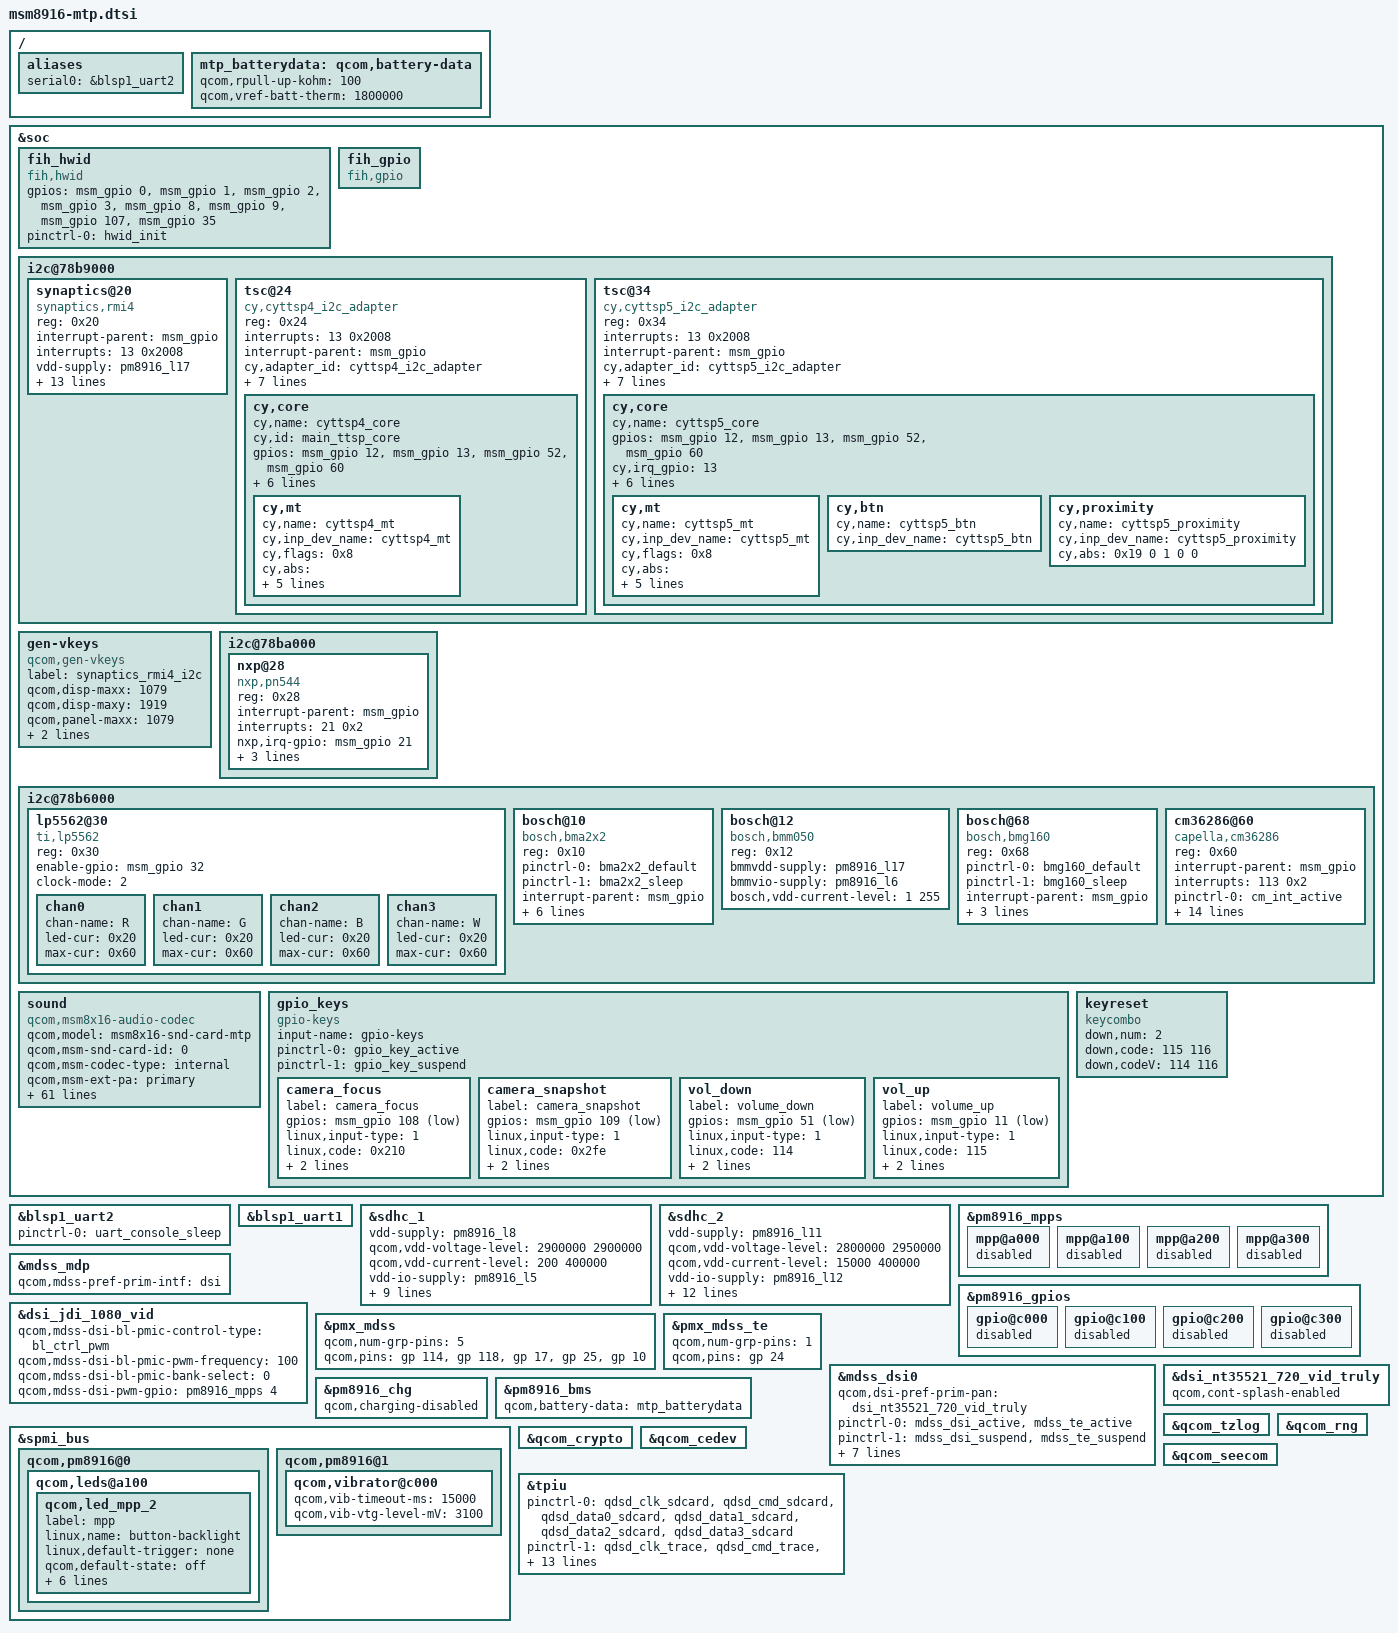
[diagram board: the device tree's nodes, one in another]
/* Copyright (c) 2014, The Linux Foundation. All rights reserved.
 *
 * This program is free software; you can redistribute it and/or modify
 * it under the terms of the GNU General Public License version 2 and
 * only version 2 as published by the Free Software Foundation.
 *
 * This program is distributed in the hope that it will be useful,
 * but WITHOUT ANY WARRANTY; without even the implied warranty of
 * MERCHANTABILITY or FITNESS FOR A PARTICULAR PURPOSE.  See the
 * GNU General Public License for more details.
 */

#include "msm8916.dtsi"
#include "msm8916-pinctrl.dtsi"
/* #include "msm8916-camera-sensor-mtp.dtsi" *//* MM-MC-BringUpImx214CameraSensor-00- */
#include "msm8916-camera-sensor-mtp-fih.dtsi"/* MM-MC-BringUpImx214CameraSensor-00+ */

/ {
	aliases {
		serial0 = &blsp1_uart2;
	};
};

&soc {
    fih_hwid {
        compatible = "fih,hwid";
        /*the gpios order must from 0-7*/
        gpios = <&msm_gpio 0 0>,   /*HW_ID_0*/
                <&msm_gpio 1 0>,   /*HW_ID_1*/
                <&msm_gpio 2 0>,   /*HW_ID_2*/
                <&msm_gpio 3 0>,   /*HW_ID_3*/
                <&msm_gpio 8 0>,   /*HW_ID_4*/
                <&msm_gpio 9 0>,   /*HW_ID_5*/
                <&msm_gpio 107 0>, /*HW_ID_6*/
                <&msm_gpio 35 0>;  /*HW_ID_7*/
        pinctrl-names = "init";
        pinctrl-0 = <&hwid_init>;
    };

    fih_gpio {
        compatible = "fih,gpio";
    };

	i2c@78b9000 { /* BLSP1 QUP5 */
		synaptics@20 {
			compatible = "synaptics,rmi4";
			reg = <0x20>;
			interrupt-parent = <&msm_gpio>;
			interrupts = <13 0x2008>;
			vdd-supply = <&pm8916_l17>;
			vcc_i2c-supply = <&pm8916_l6>;
			/* pins used by touchscreen */
			pinctrl-names = "pmx_ts_active","pmx_ts_suspend","pmx_ts_suspend";
			pinctrl-0 = <&ts_int_active &ts_reset_active>;
			pinctrl-1 = <&ts_int_suspend &ts_reset_suspend>;
			pinctrl-2 = <&ts_release>;
			synaptics,display-coords = <0 0 1079 1919>;
			synaptics,panel-coords = <0 0 1079 2084>;
			synaptics,irq-gpio = <&msm_gpio 13 0x2008>;
			synaptics,reset-gpio = <&msm_gpio 12 0x0>;
			synaptics,i2c-pull-up;
			synaptics,power-down;
			synaptics,disable-gpios;
			/* Underlying clocks used by secure touch */
			clocks = <&clock_gcc clk_gcc_blsp1_ahb_clk>,
			 <&clock_gcc clk_gcc_blsp1_qup5_i2c_apps_clk>;
			clock-names = "iface_clk", "core_clk";
		};

		tsc@24 {
			compatible = "cy,cyttsp4_i2c_adapter";
			reg = <0x24>;
			/* GPIO 38, high-to-low edge triggered */
			interrupts = <13 0x2008>;
			interrupt-parent = <&msm_gpio>;
			cy,adapter_id = "cyttsp4_i2c_adapter";
			pinctrl-names = "pmx_ts_active","pmx_ts_suspend";
			pinctrl-0 = <&ts_int_active &ts_reset_active>;
			pinctrl-1 = <&ts_int_suspend &ts_reset_suspend>;
			vdda-supply = <&pm8916_l17>;
			vddio_EVM-supply = <&pm8916_l6>;
			vddio_PD1-supply = <&pm8916_l16>;
			vddio_DEFAULT-supply = <&pm8916_l6>;
			qcom,module_adc-vadc = <&pm8916_vadc>;

			cy,core {
				cy,name = "cyttsp4_core";
				cy,id = "main_ttsp_core";

				gpios = <&msm_gpio 12 0>, <&msm_gpio 13 0>, <&msm_gpio 52 0>, <&msm_gpio 60 0>;

				cy,irq_gpio = <13>;
				cy,rst_gpio = <12>;

				/* Enable cy,max_xfer_len to limit max I2C/SPI transfer length */
				/* cy,max_xfer_len = <0x100>; */

				/* CY_CORE_FLAG_WAKE_ON_GESTURE */
				cy,flags = <1>;
				/* CY_CORE_EWG_TAP_TAP | CY_CORE_EWG_TWO_FINGER_SLIDE */
				cy,easy_wakeup_gesture = <3>;
				cy,btn_keys = <102 /* KEY_HOME */
					       139 /* KEY_MENU */
					       158 /* KEY_BACK */
					       217 /* KEY_SEARCH */
					       114 /* KEY_VOLUMEDOWN */
					       115 /* KEY_VOLUMEUP */
					       212 /* KEY_CAMERA */
					       116>; /* KEY_POWER */
				cy,btn_keys-tag = <0>;

				cy,mt {
					cy,name = "cyttsp4_mt";

					cy,inp_dev_name = "cyttsp4_mt";
					/* CY_MT_FLAG_FLIP | CY_MT_FLAG_INV_X | CY_MT_FLAG_INV_Y */
					cy,flags = <0x8>;
					cy,abs =
						/* ABS_MT_POSITION_X, CY_ABS_MIN_X, CY_ABS_MAX_X, 0, 0 */
						<0x35 0 1080 0 0
						/* ABS_MT_POSITION_Y, CY_ABS_MIN_Y, CY_ABS_MAX_Y, 0, 0 */
						0x36 0 1920 0 0
						/* ABS_MT_PRESSURE, CY_ABS_MIN_P, CY_ABS_MAX_P, 0, 0 */
						0x3a 0 255 0 0
						/* CY_IGNORE_VALUE, CY_ABS_MIN_W, CY_ABS_MAX_W, 0, 0 */
						0xffff 0 255 0 0
						/* ABS_MT_TRACKING_ID, CY_ABS_MIN_T, CY_ABS_MAX_T, 0, 0 */
						0x39 0 15 0 0
						/* ABS_MT_TOUCH_MAJOR, 0, 255, 0, 0 */
						0x30 0 255 0 0
						/* ABS_MT_TOUCH_MINOR, 0, 255, 0, 0 */
						0x31 0 255 0 0
						/* ABS_MT_ORIENTATION, -128, 127, 0, 0 */
						0x34 0xfffffed7 127 0 0>;

					cy,vkeys_x = <720>;
					cy,vkeys_y = <1280>;

					cy,virtual_keys = /* KeyCode CenterX CenterY Width Height */
						/* KEY_BACK */
						<158 1360 90 160 180
						/* KEY_MENU */
						139 1360 270 160 180
						/* KEY_HOME */
						102 1360 450 160 180
						/* KEY SEARCH */
						217 1360 630 160 180>;
				};
			};
		};

		tsc@34 {
			compatible = "cy,cyttsp5_i2c_adapter";
			reg = <0x34>;

			/* GPIO 38, high-to-low edge triggered */
			interrupts = <13 0x2008>;
			interrupt-parent = <&msm_gpio>;
			cy,adapter_id = "cyttsp5_i2c_adapter";
			pinctrl-names = "pmx_ts_active","pmx_ts_suspend";
			pinctrl-0 = <&ts_int_active &ts_reset_active>;
			pinctrl-1 = <&ts_int_suspend &ts_reset_suspend>;
			vdda-supply = <&pm8916_l17>;
			vddio_EVM-supply = <&pm8916_l6>;
			vddio_PD1-supply = <&pm8916_l16>;
			vddio_DEFAULT-supply = <&pm8916_l6>;
			qcom,module_adc-vadc = <&pm8916_vadc>;

			cy,core {
				cy,name = "cyttsp5_core";

				gpios = <&msm_gpio 12 0>, <&msm_gpio 13 0>, <&msm_gpio 52 0>, <&msm_gpio 60 0>;

				cy,irq_gpio = <13>;
				cy,rst_gpio = <12>;
				cy,hid_desc_register = <1>;
				/* CY_CORE_FLAG_WAKE_ON_GESTURE | CY_CORE_FLAG_RESTORE_PARAMETERS */
				cy,flags = <5>;
				/* CY_CORE_EWG_NONE */
				cy,easy_wakeup_gesture = <0>;
				cy,btn_keys = <172 /* KEY_HOMEPAGE */
						   /* previously was KEY_HOME, new Android versions use KEY_HOMEPAGE */
					       139 /* KEY_MENU */
					       158 /* KEY_BACK */
					       217 /* KEY_SEARCH */
					       114 /* KEY_VOLUMEDOWN */
					       115 /* KEY_VOLUMEUP */
					       212 /* KEY_CAMERA */
					       116>; /* KEY_POWER */
				cy,btn_keys-tag = <0>;

				cy,mt {
					cy,name = "cyttsp5_mt";

					cy,inp_dev_name = "cyttsp5_mt";
					/* CY_MT_FLAG_FLIP | CY_MT_FLAG_INV_X | CY_MT_FLAG_INV_Y */
					cy,flags = <0x8>;
					cy,abs =
						/* ABS_MT_POSITION_X, CY_ABS_MIN_X, CY_ABS_MAX_X, 0, 0 */
						<0x35 0 1080 0 0
						/* ABS_MT_POSITION_Y, CY_ABS_MIN_Y, CY_ABS_MAX_Y, 0, 0 */
						0x36 0 1920 0 0
						/* ABS_MT_PRESSURE, CY_ABS_MIN_P, CY_ABS_MAX_P, 0, 0 */
						0x3a 0 255 0 0
						/* CY_IGNORE_VALUE, CY_ABS_MIN_W, CY_ABS_MAX_W, 0, 0 */
						0xffff 0 255 0 0
						/* ABS_MT_TRACKING_ID, CY_ABS_MIN_T, CY_ABS_MAX_T, 0, 0 */
						0x39 0 15 0 0
						/* ABS_MT_TOUCH_MAJOR, 0, 255, 0, 0 */
						0x30 0 255 0 0
						/* ABS_MT_TOUCH_MINOR, 0, 255, 0, 0 */
						0x31 0 255 0 0
						/* ABS_MT_ORIENTATION, -127, 127, 0, 0 */
						0x34 0xffffff81 127 0 0
						/* ABS_MT_TOOL_TYPE, 0, MT_TOOL_MAX, 0, 0 */
						0x37 0 1 0 0
						/* ABS_DISTANCE, 0, 255, 0, 0 */
						0x19 0 255 0 0>;

					cy,vkeys_x = <720>;
					cy,vkeys_y = <1280>;

					cy,virtual_keys = /* KeyCode CenterX CenterY Width Height */
						/* KEY_BACK */
						<158 1360 90 160 180
						/* KEY_MENU */
						139 1360 270 160 180
						/* KEY_HOMEPAGE */
						172 1360 450 160 180
						/* KEY SEARCH */
						217 1360 630 160 180>;
				};

				cy,btn {
					cy,name = "cyttsp5_btn";

					cy,inp_dev_name = "cyttsp5_btn";
				};

				cy,proximity {
					cy,name = "cyttsp5_proximity";

					cy,inp_dev_name = "cyttsp5_proximity";
					cy,abs =
						/* ABS_DISTANCE, CY_PROXIMITY_MIN_VAL, CY_PROXIMITY_MAX_VAL, 0, 0 */
						<0x19 0 1 0 0>;
				};
			};
		};

	};

	gen-vkeys {
		compatible = "qcom,gen-vkeys";
		label = "synaptics_rmi4_i2c";
		qcom,disp-maxx = <1079>;
		qcom,disp-maxy = <1919>;
		qcom,panel-maxx = <1079>;
		qcom,panel-maxy = <2084>;
		qcom,key-codes = <158 139 172 217>;
	};

	i2c@78ba000 { /* BLSP1 QUP6 */
		nxp@28 {
			compatible = "nxp,pn544";
			reg = <0x28>;
			interrupt-parent = <&msm_gpio>;
			interrupts = <21 0x2>;
			nxp,irq-gpio=<&msm_gpio 21 0>;
			nxp,vengpio= <&msm_gpio 20 0>;
			nxp,firmgpio_EVM=<&msm_gpio 112 0>;
			nxp,firmgpio=<&msm_gpio 120 0>;
		};
	};

	i2c@78b6000 { /* BLSP1 QUP2 */
	    lp5562@30 {
	        compatible = "ti,lp5562";
	        reg = <0x30>;
                enable-gpio = <&msm_gpio 32 0>;
	        clock-mode = /bits/8 <2>;
	    
	        chan0 {
	            chan-name = "R";
	            led-cur = /bits/ 8 <0x20>;
	            max-cur = /bits/ 8 <0x60>;
	        };
	    
	        chan1 {
	            chan-name = "G";
	            led-cur = /bits/ 8 <0x20>;
	            max-cur = /bits/ 8 <0x60>;
	        };
	    
	        chan2 {
	            chan-name = "B";
	            led-cur = /bits/ 8 <0x20>;
	            max-cur = /bits/ 8 <0x60>;
	        };
	    
	        chan3 {
	            chan-name = "W";
	            led-cur = /bits/ 8 <0x20>;
	            max-cur = /bits/ 8 <0x60>;
	        };
	    };

	    bosch@10 {
		compatible = "bosch,bma2x2";
		reg = <0x10>;

		pinctrl-names = "bma_default","bma_sleep";
		pinctrl-0 = <&bma2x2_default>;
		pinctrl-1 = <&bma2x2_sleep>;
		interrupt-parent = <&msm_gpio>;
		interrupts = <69 0x00>;

		bosch,int_pin = <&msm_gpio 69 0x00>;
		bosch,layout=<0x8>;
		bmavdd-supply = <&pm8916_l17>;
		bmavio-supply = <&pm8916_l6>;
		bosch,vdd-current-level = <1 210>;
	    };

	    bosch@12 {
		compatible = "bosch,bmm050";
		reg = <0x12>;

		bmmvdd-supply = <&pm8916_l17>;
		bmmvio-supply = <&pm8916_l6>;
		bosch,vdd-current-level = <1 255>;
	    };

	    bosch@68 {
		compatible = "bosch,bmg160";
		reg = <0x68>;

		pinctrl-names = "bmg_default","bmg_sleep";
		pinctrl-0 = <&bmg160_default>;
		pinctrl-1 = <&bmg160_sleep>;
		interrupt-parent = <&msm_gpio>;
		interrupts = <115 0x00>;

		bmgvdd-supply = <&pm8916_l17>;
		bosch,vdd-current-level = <1 255>;
	    };

	    cm36286@60 {
		compatible = "capella,cm36286";
		reg = <0x60>;
		interrupt-parent = <&msm_gpio>;
		interrupts = <113 0x2>;
		pinctrl-names = "pls_active","pls_suspend";			
		pinctrl-0 = <&cm_int_active>;
		pinctrl-1 = <&cm_int_suspend>;
		intr = <&msm_gpio 113 0>;
		cm36286,slave_addr = <0x60>;
		cm36286,levels = <0x0A 0xA0 0xE1 0x140 0x280 0x500 0xA28 0x16A8 0x1F40 0x2800>;
		cm36286,ps_close_thd_set = <0x20>;
		cm36286,ps_away_thd_set = <0x10>;
		vdd-supply = <&pm8916_l17>;
		vcc_i2c-supply = <&pm8916_l6>;
		cm36286,vdd_power = < 2850000 2850000 15000 >;
		cm36286,i2c_power = < 1800000 1800000 15000 >;

		/* CM36686_ALS_IT_160ms | CM36686_ALS_PERS_4 */
		/* 0x40 | 0x8  */
		cm36286,ls_cmd = <0x48>;

		/* CM36686_PS_IT_1T | CM36686_PS_DR_1_40 | CM36686_PS_PERS_2 */
		/* 0 | 0 | 0x10 */
		cm36286,ps_conf1_val = <0x10>;

		/* CM36686_PS_MS_NORMAL | CM36686_LED_I_75 */
		/* 0 | 0x100 */
		cm36286,ps_conf3_val = <0x100>;
	    };

	};

	sound {
		compatible = "qcom,msm8x16-audio-codec";
		qcom,model = "msm8x16-snd-card-mtp";
		qcom,msm-snd-card-id = <0>;
		qcom,msm-codec-type = "internal";
		qcom,msm-ext-pa = "primary";
		qcom,msm-mclk-freq = <9600000>;
		qcom,msm-mbhc-hphl-swh = <1>;
		qcom,msm-mbhc-gnd-swh = <0>;
		qcom,msm-micbias1-ext-cap;
		qcom,msm-hs-micbias-type = "internal";
		qcom,audio-routing =
			"RX_BIAS", "MCLK",
			"SPK_RX_BIAS", "MCLK",
			"INT_LDO_H", "MCLK",
			"MIC BIAS External", "Handset Mic",
			"MIC BIAS Internal2", "Headset Mic",
			"MIC BIAS External", "Secondary Mic",
			"AMIC1", "MIC BIAS External",
			"AMIC2", "MIC BIAS Internal2",
			"AMIC3", "MIC BIAS External",
			"DMIC1", "MIC BIAS Internal1",
			"MIC BIAS Internal1", "Digital Mic1",
			"DMIC2", "MIC BIAS Internal1",
			"MIC BIAS Internal1", "Digital Mic2";
		pinctrl-names = "cdc_lines_act",
				"cdc_lines_sus",
				"cdc_lines_sec_ext_act",
				"cdc_lines_sec_ext_sus",
				"cross_conn_det_act",
				"cross_conn_det_sus";
		pinctrl-0 = <&cdc_pdm_lines_act>;
		pinctrl-1 = <&cdc_pdm_lines_sus>;
		pinctrl-2 = <&cdc_pdm_lines_act &cdc_ext_pa_act
						&cdc_ext_pa_ws_act>;
		pinctrl-3 = <&cdc_pdm_lines_sus &cdc_ext_pa_sus
						&cdc_ext_pa_ws_sus>;
		pinctrl-4 = <&cross_conn_det_act>;
		pinctrl-5 = <&cross_conn_det_sus>;
              //qcom,cdc-us-euro-gpios = <&msm_gpio 120 0>;
              qcom,cdc-vdd-spkr-pd-gpios = <&msm_gpio 116 0>;
              qcom,cdc-vdd-rcv-pd-gpios = <&msm_gpio 49 0>;
              qcom,cdc-vdd-spkr-gpios = <&msm_gpio 49 0>;
              qcom,cdc-vdd-hac-gpios = <&msm_gpio 116 0>;
		asoc-platform = <&pcm0>, <&pcm1>, <&voip>, <&voice>,
				<&loopback>, <&compress>, <&hostless>,
				<&afe>, <&lsm>, <&routing>, <&lpa>;
		asoc-platform-names = "msm-pcm-dsp.0", "msm-pcm-dsp.1",
				"msm-voip-dsp", "msm-pcm-voice", "msm-pcm-loopback",
				"msm-compress-dsp", "msm-pcm-hostless", "msm-pcm-afe",
				"msm-lsm-client", "msm-pcm-routing", "msm-pcm-lpa";
		asoc-cpu = <&dai_pri_auxpcm>, <&dai_hdmi>,
				<&dai_mi2s0>, <&dai_mi2s1>, <&dai_mi2s2>, <&dai_mi2s3>,
				<&sb_0_rx>, <&sb_0_tx>, <&sb_1_rx>, <&sb_1_tx>,
				<&sb_3_rx>, <&sb_3_tx>, <&sb_4_rx>, <&sb_4_tx>,
				<&bt_sco_rx>, <&bt_sco_tx>, <&int_fm_rx>, <&int_fm_tx>,
				<&afe_pcm_rx>, <&afe_pcm_tx>, <&afe_proxy_rx>, <&afe_proxy_tx>,
				<&incall_record_rx>, <&incall_record_tx>, <&incall_music_rx>,
				<&incall_music_2_rx>;
		asoc-cpu-names = "msm-dai-q6-auxpcm.1", "msm-dai-q6-hdmi.8",
				"msm-dai-q6-mi2s.0", "msm-dai-q6-mi2s.1",
				"msm-dai-q6-mi2s.2", "msm-dai-q6-mi2s.3",
				"msm-dai-q6-dev.16384", "msm-dai-q6-dev.16385",
				"msm-dai-q6-dev.16386", "msm-dai-q6-dev.16387",
				"msm-dai-q6-dev.16390", "msm-dai-q6-dev.16391",
				"msm-dai-q6-dev.16392", "msm-dai-q6-dev.16393",
				"msm-dai-q6-dev.12288", "msm-dai-q6-dev.12289",
				"msm-dai-q6-dev.12292", "msm-dai-q6-dev.12293",
				"msm-dai-q6-dev.224", "msm-dai-q6-dev.225",
				"msm-dai-q6-dev.241", "msm-dai-q6-dev.240",
				"msm-dai-q6-dev.32771", "msm-dai-q6-dev.32772",
				"msm-dai-q6-dev.32773", "msm-dai-q6-dev.32770";
		asoc-codec = <&stub_codec>, <&pm8916_tombak_dig>;
		asoc-codec-names = "msm-stub-codec.1", "tombak_codec";
	};
};

&blsp1_uart2 {
	status = "ok";
	pinctrl-names = "default";
	pinctrl-0 = <&uart_console_sleep>;
};

&soc {
	gpio_keys {
		compatible = "gpio-keys";
		input-name = "gpio-keys";
		pinctrl-names = "tlmm_gpio_key_active","tlmm_gpio_key_suspend";
		pinctrl-0 = <&gpio_key_active>;
		pinctrl-1 = <&gpio_key_suspend>;
		/* PERI-JC-KEYPAD_BringUp-00+[ */
		camera_focus {
			label = "camera_focus";
			gpios = <&msm_gpio 108 0x1>;
			linux,input-type = <1>;
			linux,code = <0x210>;
			gpio-key,wakeup;
			debounce-interval = <100>;
		};

		camera_snapshot {
			label = "camera_snapshot";
			gpios = <&msm_gpio 109 0x1>;
			linux,input-type = <1>;
			linux,code = <0x2fe>;
			gpio-key,wakeup;
			debounce-interval = <100>;
		};

		vol_down {
			label = "volume_down";
			gpios = <&msm_gpio 51 0x1>;
			linux,input-type = <1>;
			linux,code = <114>;
			gpio-key,wakeup;
			debounce-interval = <100>;
		};
		vol_up {
			label = "volume_up";
			gpios = <&msm_gpio 11 0x1>;
			linux,input-type = <1>;
			linux,code = <115>;
			gpio-key,wakeup;
			debounce-interval = <100>;
		};
		/* PERI-JC-KEYPAD_BringUp-00+] */
	};
	
	 /* PERI-JC-CombineKey-00+[ */
	 keyreset {
	 	compatible = "keycombo";
	 	down,num = <2>;
	 	down,code = <115 116>;
	 	down,codeV = <114 116>;
	 };
	 /* PERI-JC-CombineKey-00+] */
};

&blsp1_uart1 {
	status = "ok";
};

&sdhc_1 {
	vdd-supply = <&pm8916_l8>;
	qcom,vdd-voltage-level = <2900000 2900000>;
	qcom,vdd-current-level = <200 400000>;

	vdd-io-supply = <&pm8916_l5>;
	qcom,vdd-io-always-on;
	qcom,vdd-io-lpm-sup;
	qcom,vdd-io-voltage-level = <1800000 1800000>;
	qcom,vdd-io-current-level = <200 60000>;

	pinctrl-names = "active", "sleep";
	pinctrl-0 = <&sdc1_clk_on &sdc1_cmd_on &sdc1_data_on>;
	pinctrl-1 = <&sdc1_clk_off &sdc1_cmd_off &sdc1_data_off>;

	qcom,nonremovable;

	status = "ok";
};

&sdhc_2 {
	vdd-supply = <&pm8916_l11>;
	qcom,vdd-voltage-level = <2800000 2950000>;
	qcom,vdd-current-level = <15000 400000>;

	vdd-io-supply = <&pm8916_l12>;
	qcom,vdd-io-voltage-level = <1800000 2950000>;
	qcom,vdd-io-current-level = <200 50000>;

	pinctrl-names = "active", "sleep";
	pinctrl-0 = <&sdc2_clk_on &sdc2_cmd_on &sdc2_data_on &sdc2_cd_on>;
	pinctrl-1 = <&sdc2_clk_off &sdc2_cmd_off &sdc2_data_off &sdc2_cd_off>;

	#address-cells = <0>;
	interrupt-parent = <&sdhc_2>;
	interrupts = <0 1 2>;
	#interrupt-cells = <1>;
	interrupt-map-mask = <0xffffffff>;
	interrupt-map = <0 &intc 0 125 0
			1 &intc 0 221 0
			2 &msm_gpio 38 0>;
	interrupt-names = "hc_irq", "pwr_irq", "status_irq";
	cd-gpios = <&msm_gpio 38 0x1>;

	status = "ok";
};

&pm8916_mpps {
	mpp@a000 { /* MPP 1 */
		/* VDD_PX */
		status = "disabled";
	};

	mpp@a100 { /* MPP 2 */
		/* LED_RED_DRV */
		status = "disabled";
	};

	mpp@a200 { /* MPP 3 */
		/* VREF DAC */
		status = "disabled";
	};

	mpp@a300 { /* MPP 4 */
		/* LED_GREEN_DRV */
		status = "disabled";
	};
};

&pm8916_gpios {
	gpio@c000 { /* GPIO 1 */
		/* Battery UICC Alarm */
		status = "disabled";
	};

	gpio@c100 { /* GPIO 2 */
		/* LED_BLUE_DRV */
		status = "disabled";
	};

	gpio@c200 { /* GPIO 3 */
		/* NC, test point - PTP106 */
		status = "disabled";
	};

	gpio@c300 { /* GPIO 4 */
		/* LED_GREEN_DRV_1, but NC now. */
		status = "disabled";
	};
};

#include "dsi-panel-jdi-1080p-video.dtsi"

&mdss_mdp {
	qcom,mdss-pref-prim-intf = "dsi";
};

&dsi_jdi_1080_vid {
	qcom,mdss-dsi-bl-pmic-control-type = "bl_ctrl_pwm";
	qcom,mdss-dsi-bl-pmic-pwm-frequency = <100>;
	qcom,mdss-dsi-bl-pmic-bank-select = <0>;
	qcom,mdss-dsi-pwm-gpio = <&pm8916_mpps 4 0>;

};

&pmx_mdss {
	/* MM-GL-DISPLAY-panel-00-[
	qcom,num-grp-pins = <3>;
	qcom,pins = <&gp 97>, <&gp 25>, <&gp 98>;
	MM-GL-DISPLAY-panel-00-] */
	/* MM-GL-DISPLAY-panel-00+[ */
	qcom,num-grp-pins = <5>;
	qcom,pins = <&gp 114>, <&gp 118>, <&gp 17>, <&gp 25>, <&gp 10>;
	/* MM-GL-DISPLAY-panel-00+] */
};

&pmx_mdss_te {
	qcom,num-grp-pins = <1>;
	qcom,pins = <&gp 24>;
};

&mdss_dsi0 {
	/* MM-GL-DISPLAY-panel-00- *///qcom,dsi-pref-prim-pan = <&dsi_jdi_1080_vid>;
	qcom,dsi-pref-prim-pan = <&dsi_nt35521_720_vid_truly>;/* MM-GL-DISPLAY-panel-00+ */
	pinctrl-names = "mdss_default", "mdss_sleep";
	pinctrl-0 = <&mdss_dsi_active &mdss_te_active>;
	pinctrl-1 = <&mdss_dsi_suspend &mdss_te_suspend>;
	/* MM-GL-DISPLAY-panel-00+[ */
	qcom,platform-p5-gpio = <&msm_gpio 114 0>;
	qcom,platform-n5-gpio = <&msm_gpio 118 0>;
	qcom,platform-n5-1-gpio = <&msm_gpio 17 0>;
	/* MM-GL-DISPLAY-panel-00+] */
	/* MM-GL-DISPLAY-panel-00- *///qcom,platform-enable-gpio = <&msm_gpio 97 0>;
	qcom,platform-reset-gpio = <&msm_gpio 25 0>;
	/* MM-GL-DISPLAY-panel-00- *///qcom,platform-bklight-en-gpio = <&msm_gpio 98 0>;
	/* MM-GL-DISPLAY-panel-00+[ */
	qcom,platform-te-gpio = <&msm_gpio 24 0>;
	qcom,platform-bklight-en-gpio = <&msm_gpio 10 0>;
	qcom,regulator-ldo-mode;
	/* MM-GL-DISPLAY-panel-00+] */
};

/* MM-GL-DISPLAY-panel-00- *///&dsi_jdi_1080_vid {
&dsi_nt35521_720_vid_truly {/* MM-GL-DISPLAY-panel-00+ */
       qcom,cont-splash-enabled;
};

&pm8916_chg {
	status = "ok";
	qcom,charging-disabled;
};

/ {
	mtp_batterydata: qcom,battery-data {
		qcom,rpull-up-kohm = <100>;
		qcom,vref-batt-therm = <1800000>;

		#include "batterydata-palladium.dtsi"
	};
};

&pm8916_bms {
	status = "ok";
	qcom,battery-data = <&mtp_batterydata>;
};

&spmi_bus {
	qcom,pm8916@0 {
		qcom,leds@a100 {
			status = "okay";
			qcom,led_mpp_2 {
				label = "mpp";
				linux,name = "button-backlight";
				linux,default-trigger = "none";
				qcom,default-state = "off";
				qcom,max-current = <40>;
				qcom,current-setting = <5>;
				qcom,id = <6>;
				qcom,mode = "manual";
				qcom,source-sel = <1>;
				qcom,mode-ctrl = <0x60>;
			};
		};
	};
};

&qcom_tzlog {
	status = "okay";
};

&qcom_rng {
	status = "okay";
};

&qcom_crypto {
	status = "okay";
};

&qcom_cedev {
	status = "okay";
};

&qcom_seecom {
	status = "okay";
};

/* CoreSight */
&tpiu {
      pinctrl-names = "sdcard", "trace", "swduart",
		      "swdtrc", "jtag", "spmi";
       /* NIDnT */
      pinctrl-0 = <&qdsd_clk_sdcard &qdsd_cmd_sdcard
                  &qdsd_data0_sdcard &qdsd_data1_sdcard
                  &qdsd_data2_sdcard &qdsd_data3_sdcard>;
      pinctrl-1 = <&qdsd_clk_trace &qdsd_cmd_trace
                  &qdsd_data0_trace &qdsd_data1_trace
                  &qdsd_data2_trace &qdsd_data3_trace>;
      pinctrl-2 = <&qdsd_cmd_swduart &qdsd_data0_swduart
                  &qdsd_data1_swduart &qdsd_data2_swduart
                  &qdsd_data3_swduart>;
      pinctrl-3 = <&qdsd_clk_swdtrc &qdsd_cmd_swdtrc
                  &qdsd_data0_swdtrc &qdsd_data1_swdtrc
                  &qdsd_data2_swdtrc &qdsd_data3_swdtrc>;
      pinctrl-4 = <&qdsd_cmd_jtag &qdsd_data0_jtag
                  &qdsd_data1_jtag &qdsd_data2_jtag
                  &qdsd_data3_jtag>;
      pinctrl-5 = <&qdsd_clk_spmi &qdsd_cmd_spmi
                  &qdsd_data0_spmi &qdsd_data3_spmi>;
};

&spmi_bus {
	qcom,pm8916@1 {
		qcom,vibrator@c000 {
			status = "okay";
			qcom,vib-timeout-ms = <15000>;
			qcom,vib-vtg-level-mV = <3100>;
		};
	};
};
